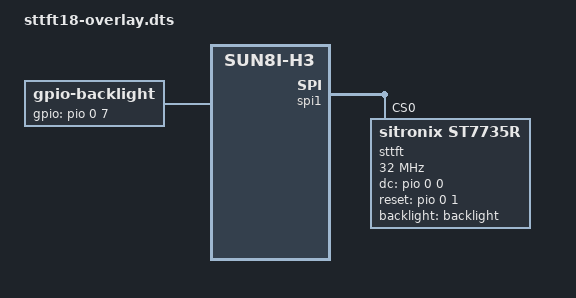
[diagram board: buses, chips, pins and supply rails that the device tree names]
/*
 * Device Tree overlay for the Sitronix 1.8" TFT
 *
 */

/dts-v1/;
/plugin/;

/ {
	compatible = "allwinner,sun8i-h3";

	fragment@0 {
		target-path = "/aliases";
		__overlay__ {
			spi1 = "/soc/spi@01c69000";
			pio = "/soc/pinctrl@01c20800";
		};
	};

	fragment@1 {
		target = <&pio>;
		__overlay__ {
			tft_pins: tft_pins {
				pins = "PA7", "PA0", "PA1";	/*BL, DC, RST */
				function = "gpio_out"; 		
				drive-strength = <40>;			/* weak output */
//				bias-disable;				
			};
		};
	};

	fragment@2 {
		target = <&spi1>;
		__overlay__ {
			/* needed to avoid dtc warning */
			#address-cells = <1>;
			#size-cells = <0>;
			status = "okay";

			sttft: sttft@0{
				compatible = "sitronix,st7735r";
				status = "okay";
				reg = <0>;
				pinctrl-names = "default";
				pinctrl-0 = <&tft_pins>;

				spi-max-frequency = <32000000>;
//				rotation = <180>;
				dc-gpios = <&pio 0 0  0>;	/* PA0, out, low */
				reset-gpios = <&pio 0 1 0>;	/* PA1, out, high */
				backlight = <&backlight>;
			};

		};
	};

	fragment@3 {
		target-path = "/soc";
		__overlay__ {
			backlight: backlight {
				compatible = "gpio-backlight";
				status = "okay";
				gpios = <&pio 0 7 0>;		/* PA7, active high */
				default-on;
			};
		};
	};

	__overrides__ {
		speed =    <&sttft>,"spi-max-frequency:0";
		rotation = <&sttft>,"rotation:0";
	};
};
